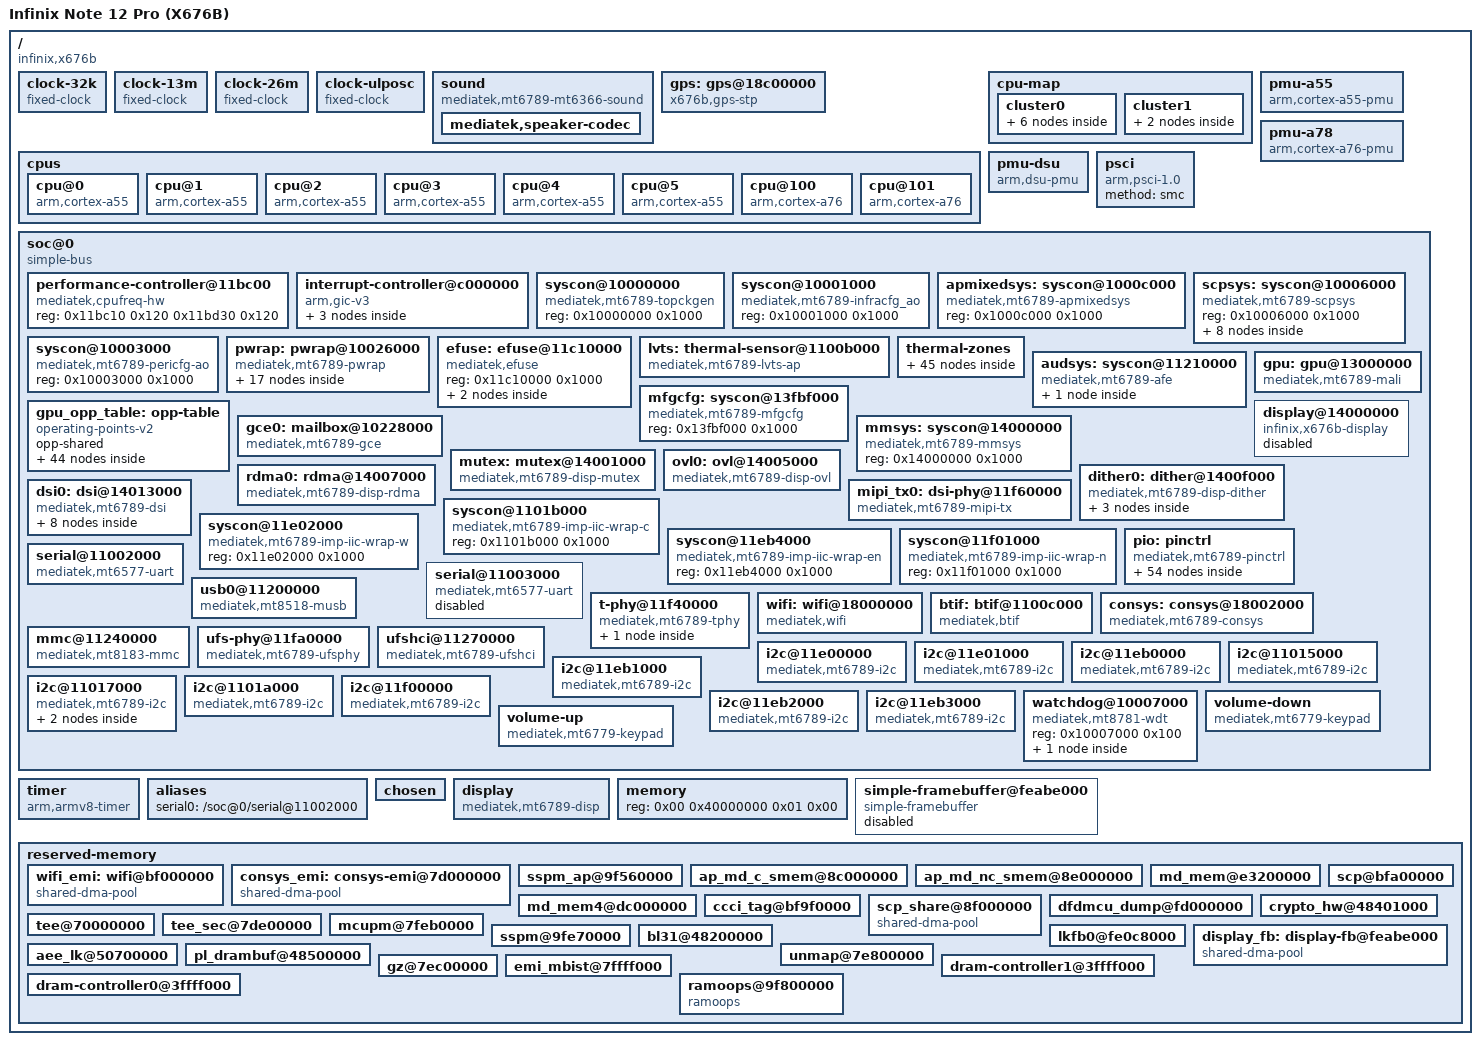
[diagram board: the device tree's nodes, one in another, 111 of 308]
/dts-v1/;

/ {
	compatible = "infinix,x676b", "mediatek,mt6789";
	#address-cells = <0x02>;
	#size-cells = <0x02>;
	interrupt-parent = <0x01>;
	model = "Infinix Note 12 Pro (X676B)";
	chassis-type = "handset";

	clock-32k {
		compatible = "fixed-clock";
		#clock-cells = <0x00>;
		clock-frequency = <0x7d00>;
		clock-output-names = "clk32k";
	};

	clock-13m {
		compatible = "fixed-clock";
		#clock-cells = <0x00>;
		clock-frequency = <0xc65d40>;
		clock-output-names = "clk13m";
	};

	clock-26m {
		compatible = "fixed-clock";
		#clock-cells = <0x00>;
		clock-frequency = <0x18cba80>;
		clock-output-names = "clk26m";
		phandle = <0x0e>;
	};

	clock-ulposc {
		compatible = "fixed-clock";
		#clock-cells = <0x00>;
		clock-frequency = <0xf7f4900>;
		clock-output-names = "ulposc";
	};

	sound: sound {
		compatible = "mediatek,mt6789-mt6366-sound";
		mediatek,platform = <&afe>;

		/* FS1559VN one-wire mode/enable line for the second
		 * (receiver / top) speaker amplifier, GPIO150.
		 */
		fs1559-extamp-gpios = <0x0d 0x96 0x00>;

		mediatek,speaker-codec {
		};
	};

	/*
	 * GPS/GNSS: STP transport + L1 LNA on GPIO25.  The vendor node is
	 * top-level (no reg); the driver only needs the pinctrl states.
	 * L5 LNA (GPIO26) is intentionally not used: that pin is the USB
	 * OTG VBUS switch on this board.
	 */
	gps: gps@18c00000 {
		compatible = "x676b,gps-stp";
		pinctrl-names = "default", "gps_l1_lna_disable",
				"gps_l1_lna_dsp_ctrl", "gps_l1_lna_enable";
		pinctrl-0 = <&gps_pins_default>;
		pinctrl-1 = <&gps_l1_lna_pins_ol>;
		pinctrl-2 = <&gps_l1_lna_pins_dsp_ctrl>;
		pinctrl-3 = <&gps_l1_lna_pins_oh>;
		emi-region = <29>;
		emi-offset = <0x400000>;
		emi-size = <0xfffff>;
		status = "okay";
	};

	cpus {
		#address-cells = <0x01>;
		#size-cells = <0x00>;

		cpu@0 {
			device_type = "cpu";
			compatible = "arm,cortex-a55";
			reg = <0x00>;
			performance-domains = <0x02 0x00>;
			enable-method = "psci";
			capacity-dmips-mhz = <0x17f>;
			phandle = <0x03>;			cpu-supply = <&mt6358_vproc12_reg>;
		};

		cpu@1 {
			device_type = "cpu";
			compatible = "arm,cortex-a55";
			reg = <0x100>;
			performance-domains = <0x02 0x00>;
			enable-method = "psci";
			capacity-dmips-mhz = <0x17f>;
			phandle = <0x04>;			cpu-supply = <&mt6358_vproc12_reg>;
		};

		cpu@2 {
			device_type = "cpu";
			compatible = "arm,cortex-a55";
			reg = <0x200>;
			performance-domains = <0x02 0x00>;
			enable-method = "psci";
			capacity-dmips-mhz = <0x17f>;
			phandle = <0x05>;			cpu-supply = <&mt6358_vproc12_reg>;
		};

		cpu@3 {
			device_type = "cpu";
			compatible = "arm,cortex-a55";
			reg = <0x300>;
			performance-domains = <0x02 0x00>;
			enable-method = "psci";
			capacity-dmips-mhz = <0x17f>;
			phandle = <0x06>;			cpu-supply = <&mt6358_vproc12_reg>;
		};

		cpu@4 {
			device_type = "cpu";
			compatible = "arm,cortex-a55";
			reg = <0x400>;
			performance-domains = <0x02 0x00>;
			enable-method = "psci";
			capacity-dmips-mhz = <0x17f>;
			phandle = <0x07>;			cpu-supply = <&mt6358_vproc12_reg>;
		};

		cpu@5 {
			device_type = "cpu";
			compatible = "arm,cortex-a55";
			reg = <0x500>;
			performance-domains = <0x02 0x00>;
			enable-method = "psci";
			capacity-dmips-mhz = <0x17f>;
			phandle = <0x08>;			cpu-supply = <&mt6358_vproc12_reg>;
		};

		cpu@100 {
			device_type = "cpu";
			compatible = "arm,cortex-a76";
			reg = <0x600>;
			performance-domains = <0x02 0x01>;
			enable-method = "psci";
			capacity-dmips-mhz = <0x400>;
			phandle = <0x09>;			cpu-supply = <&mt6358_vproc11_reg>;
		};

		cpu@101 {
			device_type = "cpu";
			compatible = "arm,cortex-a76";
			reg = <0x700>;
			performance-domains = <0x02 0x01>;
			enable-method = "psci";
			capacity-dmips-mhz = <0x400>;
			phandle = <0x0a>;			cpu-supply = <&mt6358_vproc11_reg>;
		};
	};

	cpu-map {

		cluster0 {

			core0 {
				cpu = <0x03>;
			};

			core1 {
				cpu = <0x04>;
			};

			core2 {
				cpu = <0x05>;
			};

			core3 {
				cpu = <0x06>;
			};

			core4 {
				cpu = <0x07>;
			};

			core5 {
				cpu = <0x08>;
			};
		};

		cluster1 {

			core2 {
				cpu = <0x09>;
			};

			core3 {
				cpu = <0x0a>;
			};
		};
	};

	pmu-a55 {
		compatible = "arm,cortex-a55-pmu";
		interrupt-parent = <0x01>;
		interrupts = <0x01 0x07 0x04 0x0b>;
	};

	pmu-a78 {
		compatible = "arm,cortex-a76-pmu";
		interrupt-parent = <0x01>;
		interrupts = <0x01 0x07 0x04 0x0c>;
	};

	pmu-dsu {
		compatible = "arm,dsu-pmu";
		cpus = <0x03 0x04 0x05 0x06 0x07 0x08 0x09 0x0a>;
		interrupts = <0x00 0x23 0x04 0x00>;
	};

	psci {
		compatible = "arm,psci-1.0";
		method = "smc";
	};

	soc@0 {
		compatible = "simple-bus";
		ranges = <0x00 0x00 0x00 0x20000000>;
		#address-cells = <0x01>;
		#size-cells = <0x01>;

		performance-controller@11bc00 {
			compatible = "mediatek,cpufreq-hw";
			reg = <0x11bc10 0x120 0x11bd30 0x120>;
			#performance-domain-cells = <0x01>;
			phandle = <0x02>;
		};

		interrupt-controller@c000000 {
			compatible = "arm,gic-v3";
			reg = <0xc000000 0x40000 0xc040000 0x200000>;
			#interrupt-cells = <0x04>;
			interrupt-controller;
			interrupts = <0x01 0x09 0x04 0x0b>;
			phandle = <0x01>;

			ppi-partitions {

				interrupt-partition-0 {
					affinity = <0x03 0x04 0x05 0x06 0x07 0x08>;
					phandle = <0x0b>;
				};

				interrupt-partition-1 {
					affinity = <0x09 0x0a>;
					phandle = <0x0c>;
				};
			};
		};

		syscon@10000000 {
			compatible = "mediatek,mt6789-topckgen", "mediatek,mt8781-topckgen", "syscon";
			reg = <0x10000000 0x1000>;
			#clock-cells = <0x01>;
			phandle = <0x10>;
		};

		syscon@10001000 {
			compatible = "mediatek,mt6789-infracfg_ao", "mediatek,mt8781-infracfg_ao", "syscon";
			reg = <0x10001000 0x1000>;
			#clock-cells = <0x01>;
			#reset-cells = <0x01>;
			phandle = <0x11>;

		};

		apmixedsys: syscon@1000c000 {
			compatible = "mediatek,mt6789-apmixedsys", "mediatek,mt8187-apmixedsys", "syscon";
			reg = <0x1000c000 0x1000>;
			#clock-cells = <0x01>;
		};

		scpsys: syscon@10006000 {
			compatible = "mediatek,mt6789-scpsys", "syscon", "simple-mfd";
			reg = <0x10006000 0x1000>;

			spm: power-controller {
				compatible = "mediatek,mt6789-power-controller";
				#address-cells = <0x01>;
				#size-cells = <0x00>;
				#power-domain-cells = <0x01>;

				/* CONN MTCMOS: needed by the CONSYS/Wi-Fi block */
				power-domain@1 {
					reg = <0x01>;
					#power-domain-cells = <0x00>;
				};

				/* GPU MFG hierarchy: MFG0 -> MFG1 -> MFG2/MFG3 */
				mfg0: power-domain@2 {
					reg = <0x02>;
					clocks = <0x10 105>, <0x10 104>;
					clock-names = "mfg", "alt";
					domain-supply = <&mt6358_vsram_gpu_reg>;
					#address-cells = <0x01>;
					#size-cells = <0x00>;
					#power-domain-cells = <0x01>;

					mfg1: power-domain@3 {
						reg = <0x03>;
						mediatek,infracfg = <0x11>;
						domain-supply = <&mt6358_vgpu_reg>;
						#address-cells = <0x01>;
						#size-cells = <0x00>;
						#power-domain-cells = <0x01>;

						power-domain@4 {
							reg = <0x04>;
							#power-domain-cells = <0x00>;
						};

						power-domain@5 {
							reg = <0x05>;
							#power-domain-cells = <0x00>;
						};
					};
				};

				power-domain@b {
					reg = <0x0b>;
					clocks = <0x10 118>, <0x11 37>, <0x11 32>;
					clock-names = "audio", "audio1", "audio2";
					mediatek,infracfg = <0x11>;
					#power-domain-cells = <0x00>;
				};

				/* DISP MTCMOS: needed by the display pipeline.
				 * No clocks here on purpose: the mm clock gates are
				 * handled by the mmsys driver, and we boot with
				 * clk_ignore_unused/pd_ignore_unused.
				 */
				disp: power-domain@a {
					reg = <0x0a>;
					#power-domain-cells = <0x00>;
				};
			};
		};

		syscon@10003000 {
			compatible = "mediatek,mt6789-pericfg-ao", "mediatek,mt8781-pericfg-ao", "syscon";
			reg = <0x10003000 0x1000>;
			#clock-cells = <0x01>;
		};

		/* PMIC bridge (SPI-like) + MT6366 (called mt6358 in mainline).
		 * Provides the regulators, RTC and the base for charger/battery.
		 * Clocks: infra_ao PMIC_AP(1)/PMIC_TMR(0), topckgen PWRAP_ULPOSC(0x4d).
		 * IRQ: GIC SPI 252; the PMIC IRQ arrives through the pinctrl EINT
		 * (0x0d), pin 137.
		 */
		pwrap: pwrap@10026000 {
			compatible = "mediatek,mt6789-pwrap";
			reg = <0x10026000 0x1000>;
			reg-names = "pwrap";
			interrupts = <0x00 0xfc 0x04 0x00>;
			clocks = <0x11 0x01 0x11 0x00 0x10 0x4d>;
			clock-names = "spi", "wrap", "ulposc";
			#address-cells = <0x01>;
			#size-cells = <0x00>;

			pmic: mt6358 {
				compatible = "mediatek,mt6358";
				interrupt-parent = <0x0d>;
				interrupts = <0x89 0x04 0x89 0x00>;
				interrupt-controller;
				#interrupt-cells = <0x02>;

				mt6358regulator: mt6358regulator {
					compatible = "mediatek,mt6358-regulator";

					/* SD card: VDD (VMCH) and VccQ (VMC) come from the
					 * PMIC, not from fixed regulators.
					 */
					/* supplies requested by the MT6789 consys driver */
					vcn28: vcn28 {
						regulator-name = "vcn28";
						regulator-min-microvolt = <2800000>;
						regulator-max-microvolt = <2800000>;
					};

					vcn33: vcn33 {
						regulator-name = "vcn33";
						regulator-min-microvolt = <1800000>;
						regulator-max-microvolt = <3300000>;
					};

					mt6358_vmch_reg: vmch {
						regulator-name = "vmch";
						regulator-min-microvolt = <2900000>;
						regulator-max-microvolt = <3300000>;
					};

					mt6358_vmc_reg: vmc {
						regulator-name = "vmc";
						regulator-min-microvolt = <1800000>;
						regulator-max-microvolt = <3300000>;
					};

					vcn18: vcn18 {
						regulator-name = "vcn18";
						regulator-min-microvolt = <1800000>;
						regulator-max-microvolt = <1800000>;
					};

					vpa: vpa {
						regulator-name = "vpa";
						regulator-min-microvolt = <500000>;
						regulator-max-microvolt = <3650000>;
					};

					/* GPU rails: MT6366 buck_vgpu + ldo_vsram_gpu (coupled) */
					mt6358_vgpu_reg: vgpu {
						regulator-name = "vgpu";
						regulator-min-microvolt = <0x7a120>;
						regulator-max-microvolt = <0x13bdb6>;
						regulator-ramp-delay = <0x186a>;
						regulator-enable-ramp-delay = <0xc8>;
						regulator-allowed-modes = <0x00 0x01>;
						regulator-coupled-with = <&mt6358_vsram_gpu_reg>;
						regulator-coupled-max-spread = <0x186a0>;
					};

					mt6358_vsram_gpu_reg: vsram-gpu {
						regulator-name = "vsram_gpu";
						regulator-min-microvolt = <0x7a120>;
						regulator-max-microvolt = <0x13bdb6>;
						regulator-ramp-delay = <0x186a>;
						regulator-enable-ramp-delay = <0xf0>;
						regulator-coupled-with = <&mt6358_vgpu_reg>;
						regulator-coupled-max-spread = <0x186a0>;
					};

					mt6358_vproc11_reg: vproc11 {
						regulator-name = "vproc11";
						regulator-min-microvolt = <0x7a120>;
						regulator-max-microvolt = <0x13bdb6>;
						regulator-enable-ramp-delay = <0xc8>;
						regulator-always-on;
						regulator-allowed-modes = <0x00 0x01>;
					};

					mt6358_vproc12_reg: vproc12 {
						regulator-name = "vproc12";
						regulator-min-microvolt = <0x7a120>;
						regulator-max-microvolt = <0x13bdb6>;
						regulator-enable-ramp-delay = <0xc8>;
						regulator-always-on;
						regulator-allowed-modes = <0x00 0x01>;
					};
				};

				mt6358rtc: mt6358rtc {
					compatible = "mediatek,mt6358-rtc";
					#address-cells = <0x01>;
					#size-cells = <0x01>;
				};

				mt6358keys: mt6358keys {
					compatible = "mediatek,mt6358-keys";
				};

				mt6358adc: mt6358-adc {
					compatible = "mediatek,mt6358-auxadc";
					#io-channel-cells = <0x01>;
				};

				mt6358bat: battery {
					compatible = "mediatek,mt6358-battery";
					mediatek,charger = <&rt9471_chg>;
				};

				mt6358sound: mt6358-sound {
					compatible = "mediatek,mt6358-sound";
					mediatek,dmic-mode = <0x00>;
				};
			};
		};

		/* efuse (nvmem) — used for LVTS calibration */
		efuse: efuse@11c10000 {
			compatible = "mediatek,efuse";
			reg = <0x11c10000 0x1000>;
			#address-cells = <0x01>;
			#size-cells = <0x01>;

			lvts_e_data1: data1 {
				reg = <0x1b4 0x2c>;
			};

			lvts_e_data2: data2 {
				reg = <0x2f8 0x08>;
			};
		};

		/* SoC thermal sensors. There is no mt6789 support in mainline yet, so use
		 * mt8192 (same block at 0x1100b000).
		 */
		lvts: thermal-sensor@1100b000 {
			compatible = "mediatek,mt6789-lvts-ap";
			reg = <0x1100b000 0xc00>;
			interrupts = <0x00 0xc9 0x04 0x00>;
			clocks = <0x11 0x04>;
			clock-names = "lvts_clk";
			resets = <0x11 0x00>;
			nvmem-cells = <&lvts_e_data1>, <&lvts_e_data2>;
			nvmem-cell-names = "lvts-calib-data-1", "lvts-calib-data-2";
			#thermal-sensor-cells = <0x01>;
		};

		thermal-zones {
			cpu_little1-thermal {
				polling-delay = <0x3e8>;
				polling-delay-passive = <0xfa>;
				thermal-sensors = <&lvts 0>;

				trips {
					cpu_little1_crit: trip-crit {
						temperature = <0x1adb0>;
						hysteresis = <0x7d0>;
						type = "critical";
					};
				};
			};

			cpu_little2-thermal {
				polling-delay = <0x3e8>;
				polling-delay-passive = <0xfa>;
				thermal-sensors = <&lvts 1>;

				trips {
					cpu_little2_crit: trip-crit {
						temperature = <0x1adb0>;
						hysteresis = <0x7d0>;
						type = "critical";
					};
				};
			};

			cpu_little3-thermal {
				polling-delay = <0x3e8>;
				polling-delay-passive = <0xfa>;
				thermal-sensors = <&lvts 2>;

				trips {
					cpu_little3_crit: trip-crit {
						temperature = <0x1adb0>;
						hysteresis = <0x7d0>;
						type = "critical";
					};
				};
			};

			cpu_little4-thermal {
				polling-delay = <0x3e8>;
				polling-delay-passive = <0xfa>;
				thermal-sensors = <&lvts 3>;

				trips {
					cpu_little4_crit: trip-crit {
						temperature = <0x1adb0>;
						hysteresis = <0x7d0>;
						type = "critical";
					};
				};
			};

			cpu_little5-thermal {
				polling-delay = <0x3e8>;
				polling-delay-passive = <0xfa>;
				thermal-sensors = <&lvts 4>;

				trips {
					cpu_little5_crit: trip-crit {
						temperature = <0x1adb0>;
						hysteresis = <0x7d0>;
						type = "critical";
					};
				};
			};

			cpu_little6-thermal {
				polling-delay = <0x3e8>;
				polling-delay-passive = <0xfa>;
				thermal-sensors = <&lvts 5>;

				trips {
					cpu_little6_crit: trip-crit {
						temperature = <0x1adb0>;
						hysteresis = <0x7d0>;
						type = "critical";
					};
				};
			};

			cpu_big1-thermal {
				polling-delay = <0x3e8>;
				polling-delay-passive = <0xfa>;
				thermal-sensors = <&lvts 6>;

				trips {
					cpu_big1_crit: trip-crit {
						temperature = <0x1adb0>;
						hysteresis = <0x7d0>;
						type = "critical";
					};
				};
			};

			cpu_big2-thermal {
				polling-delay = <0x3e8>;
				polling-delay-passive = <0xfa>;
				thermal-sensors = <&lvts 7>;

				trips {
					cpu_big2_crit: trip-crit {
						temperature = <0x1adb0>;
						hysteresis = <0x7d0>;
						type = "critical";
					};
				};
			};

			gpu0-thermal {
				polling-delay = <0x3e8>;
				polling-delay-passive = <0xfa>;
				thermal-sensors = <&lvts 8>;

				trips {
					gpu0_alert: trip-alert {
						temperature = <0x14c08>;
						hysteresis = <0x7d0>;
						type = "passive";
					};

					gpu0_crit: trip-crit {
						temperature = <0x1adb0>;
						hysteresis = <0x7d0>;
						type = "critical";
					};
				};

				cooling-maps {
					map0 {
						trip = <&gpu0_alert>;
						cooling-device = <&gpu 0xffffffff 0xffffffff>;
					};
				};
			};

			gpu1-thermal {
				polling-delay = <0x3e8>;
				polling-delay-passive = <0xfa>;
				thermal-sensors = <&lvts 9>;

				trips {
					gpu1_alert: trip-alert {
						temperature = <0x14c08>;
						hysteresis = <0x7d0>;
						type = "passive";
					};

					gpu1_crit: trip-crit {
						temperature = <0x1adb0>;
						hysteresis = <0x7d0>;
						type = "critical";
					};
				};

				cooling-maps {
					map0 {
						trip = <&gpu1_alert>;
						cooling-device = <&gpu 0xffffffff 0xffffffff>;
					};
				};
			};

			ts3_2-thermal {
				polling-delay = <0x3e8>;
				polling-delay-passive = <0xfa>;
				thermal-sensors = <&lvts 10>;

				trips {
					ts3_2_crit: trip-crit {
						temperature = <0x1adb0>;
						hysteresis = <0x7d0>;
						type = "critical";
					};
				};
			};

			ts3_3-thermal {
				polling-delay = <0x3e8>;
				polling-delay-passive = <0xfa>;
				thermal-sensors = <&lvts 11>;

				trips {
					ts3_3_crit: trip-crit {
						temperature = <0x1adb0>;
						hysteresis = <0x7d0>;
						type = "critical";
					};
				};
			};

			ts4_0-thermal {
				polling-delay = <0x3e8>;
				polling-delay-passive = <0xfa>;
				thermal-sensors = <&lvts 12>;

				trips {
					ts4_0_crit: trip-crit {
						temperature = <0x1adb0>;
						hysteresis = <0x7d0>;
						type = "critical";
					};
				};
			};

		};

		audsys: syscon@11210000 {
			compatible = "mediatek,mt6789-afe", "mediatek,mt8781-afe", "syscon";
			reg = <0x11210000 0x2000>;
			#clock-cells = <0x01>;
			power-domains = <&spm 0x0b>;

			afe: audio-controller {
				compatible = "mediatek,mt6789-sound";
				interrupts = <0x00 0xea 0x04 0x00>;
				topckgen = <0x10>;
				apmixedsys = <&apmixedsys>;
				infracfg = <0x11>;
				clocks = 
				<&audsys 0>,
				<&audsys 6>,
				<&audsys 7>,
				<&audsys 5>,
				<&audsys 1>,
				<&audsys 2>,
				<&audsys 4>,
				<&audsys 3>,
				<&audsys 8>,
				<&audsys 9>,
				<0x11 32>,
				<0x11 37>,
				<&audsys 14>,
				<&audsys 15>,
				<&audsys 16>,
				<&audsys 17>,
				<&audsys 18>,
				<&audsys 19>,
				<&audsys 20>,
				<&audsys 10>,
				<&audsys 11>,
				<&audsys 12>,
				<&audsys 13>,
				<&apmixedsys 11>,
				<&apmixedsys 12>,
				<0x10 117>,
				<0x10 118>,
				<0x10 3>,
				<0x10 135>,
				<0x10 36>,
				<0x10 136>,
				<0x10 94>,
				<0x10 131>,
				<0x10 38>,
				<0x10 39>,
				<0x10 132>,
				<0x10 41>,
				<0x10 42>,
				<0x10 148>,
				<0x10 149>,
				<0x10 150>,
				<0x10 151>,
				<0x10 158>,
				<0x10 159>,
				<0x10 160>,
				<0x10 161>,
				<0x10 162>,
				<0x10 163>,
				<0x10 164>,
				<0x10 142>,
				<0x10 55>;
				pinctrl-names = "aud_clk_mosi_off", "aud_clk_mosi_on",
						"aud_clk_miso_off", "aud_clk_miso_on",
						"aud_dat_mosi_off", "aud_dat_mosi_on",
						"aud_dat_miso0_off", "aud_dat_miso0_on",
						"aud_dat_miso1_off", "aud_dat_miso1_on",
						"aud_gpio_i2s0_off", "aud_gpio_i2s0_on",
						"aud_gpio_i2s3_off", "aud_gpio_i2s3_on",
						"vow_dat_miso_off", "vow_dat_miso_on",
						"vow_clk_miso_off", "vow_clk_miso_on";
				pinctrl-0 = <&aud_clk_mosi_off>;
				pinctrl-1 = <&aud_clk_mosi_on>;
				pinctrl-2 = <&aud_clk_miso_off>;
				pinctrl-3 = <&aud_clk_miso_on>;
				pinctrl-4 = <&aud_dat_mosi_off>;
				pinctrl-5 = <&aud_dat_mosi_on>;
				pinctrl-6 = <&aud_dat_miso0_off>;
				pinctrl-7 = <&aud_dat_miso0_on>;
				pinctrl-8 = <&aud_dat_miso1_off>;
				pinctrl-9 = <&aud_dat_miso1_on>;
				pinctrl-10 = <&aud_gpio_i2s0_off>;
				pinctrl-11 = <&aud_gpio_i2s0_on>;
				pinctrl-12 = <&aud_gpio_i2s3_off>;
				pinctrl-13 = <&aud_gpio_i2s3_on>;
				pinctrl-14 = <&vow_dat_miso_off>;
				pinctrl-15 = <&vow_dat_miso_on>;
				pinctrl-16 = <&vow_clk_miso_off>;
				pinctrl-17 = <&vow_clk_miso_on>;
				clock-names = 
				      "aud_afe_clk",
				      "aud_dac_clk",
				      "aud_dac_predis_clk",
				      "aud_adc_clk",
				      "aud_apll22m_clk",
				      "aud_apll24m_clk",
				      "aud_apll1_tuner_clk",
				      "aud_apll2_tuner_clk",
				      "aud_tml_clk",
				      "aud_nle",
				      "aud_infra_clk",
				      "aud_infra_26m_clk",
				      "aud_general3_asrc",
				      "aud_connsys_i2s_asrc",
				      "aud_general1_asrc",
				      "aud_general2_asrc",
				      "aud_dac_hires_clk",
				      "aud_adc_hires_clk",
				      "aud_adc_hires_tml",
				      "aud_i2s1_bclk",
				      "aud_i2s2_bclk",
				      "aud_i2s3_bclk",
				      "aud_i2s4_bclk",
				      "aud_clk_apmixed_apll1",
				      "aud_clk_apmixed_apll2",
				      "top_mux_audio",
				      "top_mux_audio_int",
				      "top_mainpll_d4_d4",
				      "top_mux_aud_1",
				      "top_apll1_ck",
				      "top_mux_aud_2",
				      "top_apll2_ck",
				      "top_mux_aud_eng1",
				      "top_apll1_d4",
				      "top_apll1_d8",
				      "top_mux_aud_eng2",
				      "top_apll2_d4",
				      "top_apll2_d8",
				      "top_i2s0_m_sel",
				      "top_i2s1_m_sel",
				      "top_i2s2_m_sel",
				      "top_i2s3_m_sel",
				      "top_apll12_div0",
				      "top_apll12_div1",
				      "top_apll12_div2",
				      "top_apll12_div3",
				      "top_apll12_div4",
				      "top_apll12_divb",
				      "top_apll12_div5",
				      "top_mux_audio_h",
				      "top_clk26m_clk";
			};
		};

		mfgcfg: syscon@13fbf000 {
			compatible = "mediatek,mt6789-mfgcfg", "mediatek,mt6789-mfg", "mediatek,mt8781-mfg", "syscon";
			reg = <0x13fbf000 0x1000>;
			#clock-cells = <0x01>;
		};

		gpu: gpu@13000000 {
			compatible = "mediatek,mt6789-mali", "arm,mali-valhall-jm";
			reg = <0x13000000 0x4000>;
			interrupts = <0x00 0x18e 0x04 0x00>,
				     <0x00 0x18d 0x04 0x00>,
				     <0x00 0x18c 0x04 0x00>;
			interrupt-names = "job", "mmu", "gpu";
			clocks = <&mfgcfg 0x00>;
			power-domains = <&spm 0x04>, <&spm 0x05>;
			power-domain-names = "core0", "core1";
			operating-points-v2 = <&gpu_opp_table>;
			mali-supply = <&mt6358_vgpu_reg>;
			#cooling-cells = <0x02>;
			status = "okay";
		};

		gpu_opp_table: opp-table {
			compatible = "operating-points-v2";
			opp-shared;

			opp00 { opp-hz = /bits/ 64 <1100000000>; opp-microvolt = <850000>; };
			opp01 { opp-hz = /bits/ 64 <1086000000>; opp-microvolt = <843750>; };
			opp02 { opp-hz = /bits/ 64 <1072000000>; opp-microvolt = <837500>; };
			opp03 { opp-hz = /bits/ 64 <1058000000>; opp-microvolt = <831250>; };
			opp04 { opp-hz = /bits/ 64 <1045000000>; opp-microvolt = <825000>; };
			opp05 { opp-hz = /bits/ 64 <1031000000>; opp-microvolt = <818750>; };
			opp06 { opp-hz = /bits/ 64 <1017000000>; opp-microvolt = <812500>; };
			opp07 { opp-hz = /bits/ 64 <1003000000>; opp-microvolt = <806250>; };
			opp09 { opp-hz = /bits/ 64 <976000000>; opp-microvolt = <793750>; };
			opp10 { opp-hz = /bits/ 64 <962000000>; opp-microvolt = <781250>; };
			opp11 { opp-hz = /bits/ 64 <948000000>; opp-microvolt = <775000>; };
			opp12 { opp-hz = /bits/ 64 <935000000>; opp-microvolt = <768750>; };
			opp13 { opp-hz = /bits/ 64 <921000000>; opp-microvolt = <762500>; };
			opp14 { opp-hz = /bits/ 64 <907000000>; opp-microvolt = <756250>; };
			opp15 { opp-hz = /bits/ 64 <893000000>; opp-microvolt = <750000>; };
			opp16 { opp-hz = /bits/ 64 <880000000>; opp-microvolt = <743750>; };
			opp17 { opp-hz = /bits/ 64 <868000000>; opp-microvolt = <737500>; };
			opp18 { opp-hz = /bits/ 64 <857000000>; opp-microvolt = <731250>; };
			opp19 { opp-hz = /bits/ 64 <846000000>; opp-microvolt = <725000>; };
			opp20 { opp-hz = /bits/ 64 <835000000>; opp-microvolt = <718750>; };
			opp21 { opp-hz = /bits/ 64 <823000000>; opp-microvolt = <712500>; };
			opp22 { opp-hz = /bits/ 64 <812000000>; opp-microvolt = <706250>; };
			opp23 { opp-hz = /bits/ 64 <801000000>; opp-microvolt = <706250>; };
			opp24 { opp-hz = /bits/ 64 <790000000>; opp-microvolt = <700000>; };
			opp25 { opp-hz = /bits/ 64 <778000000>; opp-microvolt = <693750>; };
			opp26 { opp-hz = /bits/ 64 <767000000>; opp-microvolt = <687500>; };
			opp27 { opp-hz = /bits/ 64 <756000000>; opp-microvolt = <681250>; };
			opp28 { opp-hz = /bits/ 64 <745000000>; opp-microvolt = <675000>; };
			opp29 { opp-hz = /bits/ 64 <733000000>; opp-microvolt = <668750>; };
			opp30 { opp-hz = /bits/ 64 <722000000>; opp-microvolt = <662500>; };
			opp31 { opp-hz = /bits/ 64 <711000000>; opp-microvolt = <656250>; };
			opp32 { opp-hz = /bits/ 64 <700000000>; opp-microvolt = <650000>; };
			opp33 { opp-hz = /bits/ 64 <674000000>; opp-microvolt = <643750>; };
			opp34 { opp-hz = /bits/ 64 <648000000>; opp-microvolt = <637500>; };
			opp35 { opp-hz = /bits/ 64 <622000000>; opp-microvolt = <631250>; };
			opp36 { opp-hz = /bits/ 64 <596000000>; opp-microvolt = <625000>; };
			opp37 { opp-hz = /bits/ 64 <570000000>; opp-microvolt = <618750>; };
			opp38 { opp-hz = /bits/ 64 <545000000>; opp-microvolt = <612500>; };
			opp39 { opp-hz = /bits/ 64 <519000000>; opp-microvolt = <606250>; };
			opp40 { opp-hz = /bits/ 64 <493000000>; opp-microvolt = <600000>; };
			opp41 { opp-hz = /bits/ 64 <467000000>; opp-microvolt = <593750>; };
			opp42 { opp-hz = /bits/ 64 <441000000>; opp-microvolt = <587500>; };
			opp43 { opp-hz = /bits/ 64 <415000000>; opp-microvolt = <581250>; };
			opp44 { opp-hz = /bits/ 64 <390000000>; opp-microvolt = <575000>; };
		};

		gce0: mailbox@10228000 {
			compatible = "mediatek,mt6789-gce";
			reg = <0x10228000 0x4000>;
			interrupts = <0x00 235 0x04 0x00>;
			#mbox-cells = <0x02>;
			clocks = <0x11 0x02>;		/* infracfg_ao CLK_IFRAO_GCE */
			clock-names = "gce";
		};

		mmsys: syscon@14000000 {
			compatible = "mediatek,mt6789-mmsys", "mediatek,mt8781-mmsys", "syscon";
			reg = <0x14000000 0x1000>;
			#clock-cells = <0x01>;
		};

		/* Minimal DRM/KMS driver reusing the LK-initialized pipeline */
		display@14000000 {
			compatible = "infinix,x676b-display";
			reg = <0x14000000 0x14000>;
			/* Scanout buffer lives where LK had its framebuffer, so the
			 * display SMI window set up by LK covers it.
			 */
			memory-region = <&display_fb>;
			status = "disabled";
		};

		/* ---- mainline mediatek-drm pipeline (X676B) ---- */
		mutex: mutex@14001000 {
			compatible = "mediatek,mt6789-disp-mutex";
			reg = <0x14001000 0x1000>;
			interrupts = <0x00 285 0x04 0x00>;
			power-domains = <&spm 0x0a>;
			clocks = <&mmsys 0x00>;		/* CLK_MM_DISP_MUTEX0 */
			status = "okay";
		};

		ovl0: ovl@14005000 {
			compatible = "mediatek,mt6789-disp-ovl";
			reg = <0x14005000 0x1000>;
			interrupts = <0x00 287 0x04 0x00>;
			power-domains = <&spm 0x0a>;
			clocks = <&mmsys 0x02>;		/* CLK_MM_DISP_OVL0 */
			status = "okay";
		};

		rdma0: rdma@14007000 {
			compatible = "mediatek,mt6789-disp-rdma";
			reg = <0x14007000 0x1000>;
			interrupts = <0x00 289 0x04 0x00>;
			power-domains = <&spm 0x0a>;
			clocks = <&mmsys 0x03>;		/* CLK_MM_DISP_RDMA0 */
			mediatek,rdma-fifo-size = <48992>;
			status = "okay";
		};

		dither0: dither@1400f000 {
			compatible = "mediatek,mt6789-disp-dither";
			reg = <0x1400f000 0x1000>;
			interrupts = <0x00 297 0x04 0x00>;
			power-domains = <&spm 0x0a>;
			clocks = <&mmsys 0x0e>;		/* CLK_MM_DISP_DITHER0 */
			status = "okay";

			ports {
				#address-cells = <0x01>;
				#size-cells = <0x00>;

				port@0 {
					reg = <0x00>;
					dither0_out: endpoint {
						remote-endpoint = <&dsi0_in>;
					};
				};
			};
		};

		mipi_tx0: dsi-phy@11f60000 {
			compatible = "mediatek,mt6789-mipi-tx",
			             "mediatek,mt8183-mipi-tx";
			reg = <0x11f60000 0x1000>;
			clocks = <0x0e>;		/* clk26m */
			#clock-cells = <0x00>;
			#phy-cells = <0x00>;
			clock-output-names = "mipi_tx0_pll";
			status = "okay";
		};

		dsi0: dsi@14013000 {
			compatible = "mediatek,mt6789-dsi";
			reg = <0x14013000 0x1000>;
			interrupts = <0x00 301 0x04 0x00>;
			power-domains = <&spm 0x0a>;
			clocks = <&mmsys 0x10>,		/* CLK_MM_DSI0 */
			         <&mmsys 0x15>,		/* CLK_MM_DSI0_DSI_CK_DOMAIN */
			         <&mipi_tx0>;
			clock-names = "engine", "digital", "hs";
			phys = <&mipi_tx0>;
			phy-names = "dphy";
			/*
			 * The vendor runs this panel at 1120 Mbit/s per lane
			 * (4 lanes).  It does not follow from the 167.67 MHz
			 * mode clock: in command mode the RDMA feeds the DSI
			 * as fast as the link allows, and 15.5 ms per frame
			 * (the derived 1006 Mbit/s) leaves no room for 60 Hz.
			 */
			mediatek,data-rate-mbps = <1120>;
			#address-cells = <0x01>;
			#size-cells = <0x00>;
			status = "okay";

			panel1: panel@0 {
				compatible = "ilitek,ili7835";
				reg = <0x00>;
				reset-gpios = <&pio 0x55 0x00>;	/* pin 85 */
				bias-gpios = <&pio 0x40 0x00>;	/* pin 64 */

				port {
					#address-cells = <0x01>;
					#size-cells = <0x00>;

					panel_in: endpoint@0 {
						reg = <0x00>;
						remote-endpoint = <&dsi0_out>;
					};
				};
			};

			ports {
				#address-cells = <0x01>;
				#size-cells = <0x00>;

				port@0 {
					#address-cells = <0x01>;
					#size-cells = <0x00>;
					reg = <0x00>;
					dsi0_in: endpoint@0 {
						reg = <0x00>;
						remote-endpoint = <&dither0_out>;
					};
				};

				port@1 {
					#address-cells = <0x01>;
					#size-cells = <0x00>;
					reg = <0x01>;
					dsi0_out: endpoint@0 {
						reg = <0x00>;
						remote-endpoint = <&panel_in>;
					};
				};
			};
		};

		syscon@1101b000 {
			compatible = "mediatek,mt6789-imp-iic-wrap-c", "syscon";
			phandle = <0x30>;
			reg = <0x1101b000 0x1000>;
			#clock-cells = <0x01>;
		};

		syscon@11e02000 {
			compatible = "mediatek,mt6789-imp-iic-wrap-w", "syscon";
			phandle = <0x31>;
			reg = <0x11e02000 0x1000>;
			#clock-cells = <0x01>;
		};

		syscon@11eb4000 {
			compatible = "mediatek,mt6789-imp-iic-wrap-en", "syscon";
			phandle = <0x32>;
			reg = <0x11eb4000 0x1000>;
			#clock-cells = <0x01>;
		};

		syscon@11f01000 {
			compatible = "mediatek,mt6789-imp-iic-wrap-n", "syscon";
			phandle = <0x33>;
			reg = <0x11f01000 0x1000>;
			#clock-cells = <0x01>;
		};

		pio: pinctrl {
			compatible = "mediatek,mt6789-pinctrl", "mediatek,mt8781-pinctrl";
			reg = <0x10005000 0x1000 0x11c30000 0x1000 0x11d10000 0x1000 0x11d40000 0x1000 0x11e20000 0x1000 0x11e60000 0x1000 0x11ea0000 0x1000 0x1000b000 0x1000>;
			reg-names = "iocfg0", "iocfg_rb", "iocfg_bm", "iocfg_br", "iocfg_lm", "iocfg_bl", "iocfg_rt", "eint";
			gpio-controller;
			#gpio-cells = <0x02>;
			gpio-ranges = <&pio 0x00 0x00 0xbc>;

			interrupt-controller;
			#interrupt-cells = <0x02>;
			/* EINT summary IRQ: GIC SPI 244 (stock eint node
			 * apirq@1000b000 uses <0 0xf4 4 0>); registers and
			 * reg-names already include the "eint" region.
			 */
			interrupts = <0x00 0xf4 0x04 0x00>;
			phandle = <0x0d>;

			/* GPIO12 powers the gate IC that feeds the speaker
			 * amplifier (stock DT: gate-power-gpios = <&pio 12 0>).
			 * Without it the speaker amp stays unpowered.
			 */
			gate_ic_power: gate-ic-power {
				gpio-hog;
				gpios = <0x0c 0x00>;
				output-high;
				line-name = "gate-ic-power";
			};

			/* GPIO153 enables the speaker amplifier (stock overlay:
			 * fs1559_dual_speaker_gpio = <&pio 153 0>). It is
			 * required in addition to the gate IC power above.
			 */
			spk_amp_enable: spk-amp-enable {
				gpio-hog;
				gpios = <0x99 0x00>;
				output-high;
				line-name = "spk-amp-enable";
			};
					mmc1-pins {
				phandle = <0x14>;

				pins-cmd-dat {
					pinmux = <0x4901 0x4a01 0x4b01 0x4c01 0x4801>;
					input-enable;
					/* MT6789 drive steps are 2/4 mA: 3 mA is
					 * rejected and would abort the whole group,
					 * leaving the lines without pull-ups.
					 */
					drive-strength = <0x04>;
					bias-pull-up = <0x65>;
					};

				pins-clk {
					pinmux = <0x4701>;
					drive-strength = <0x04>;
					bias-pull-down = <0x66>;
					};
			};



			aud_clk_mosi_off: aud_clk_mosi_off {

				pins_cmd0_dat {
					pinmux = <0xa900>;
					input-enable;
					bias-pull-down;
				};
			};

			aud_clk_mosi_on: aud_clk_mosi_on {

				pins_cmd0_dat {
					pinmux = <0xa901>;
					input-schmitt-enable;
					bias-disable;
				};
			};

			aud_clk_miso_off: aud_clk_miso_off {

				pins_cmd0_dat {
					pinmux = <0xad00>;
					input-enable;
					bias-pull-down;
				};
			};

			aud_clk_miso_on: aud_clk_miso_on {

				pins_cmd0_dat {
					pinmux = <0xad01>;
					input-schmitt-enable;
					bias-disable;
				};
			};

			aud_dat_mosi_off: aud_dat_mosi_off {

				pins_cmd0_dat {
					pinmux = <0xab00>;
					input-enable;
					bias-pull-down;
				};

				pins_cmd1_dat {
					pinmux = <0xac00>;
					input-enable;
					bias-pull-down;
				};
			};

			aud_dat_mosi_on: aud_dat_mosi_on {

				pins_cmd0_dat {
					pinmux = <0xab01>;
					input-schmitt-enable;
					bias-disable;
				};

				pins_cmd1_dat {
					pinmux = <0xac01>;
					input-schmitt-enable;
					bias-disable;
				};
			};

			aud_dat_miso0_off: aud_dat_miso0_off {

				pins_cmd1_dat {
					pinmux = <0xaf00>;
					input-enable;
					bias-pull-down;
				};
			};

			aud_dat_miso0_on: aud_dat_miso0_on {

				pins_cmd1_dat {
					pinmux = <0xaf01>;
					input-schmitt-enable;
					bias-disable;
				};
			};

			aud_dat_miso1_off: aud_dat_miso1_off {

				pins_cmd1_dat {
					pinmux = <0xb000>;
					input-enable;
					bias-disable;
				};
			};

			aud_dat_miso1_on: aud_dat_miso1_on {

				pins_cmd1_dat {
					pinmux = <0xb001>;
					input-schmitt-enable;
					bias-disable;
				};
			};

			aud_gpio_i2s0_off: aud_gpio_i2s0_off {

				pins_cmd1_dat {
					pinmux = <0x3500>;
					input-enable;
					bias-pull-down;
				};
			};

			aud_gpio_i2s0_on: aud_gpio_i2s0_on {

				pins_cmd1_dat {
					pinmux = <0x3502>;
					input-schmitt-enable;
					bias-disable;
				};
			};

			gps_pins_default: gps_default {
			};

			gps_l1_lna_pins_ol: gps_l1_lna@0 {
				pins_cmd_dat {
					output-low;
					pinmux = <0x1900>;
				};
			};

			gps_l1_lna_pins_dsp_ctrl: gps_l1_lna@1 {
				pins_cmd_dat {
					pinmux = <0x1902>;
				};
			};

			gps_l1_lna_pins_oh: gps_l1_lna@2 {
				pins_cmd_dat {
					output-high;
					pinmux = <0x1900>;
				};
			};

			aud_gpio_i2s3_off: aud_gpio_i2s3_off {

				pins_cmd1_dat {
					pinmux = <0x3200>;
					input-enable;
					bias-pull-down;
				};

				pins_cmd2_dat {
					pinmux = <0x3300>;
					input-enable;
					bias-pull-down;
				};

				pins_cmd3_dat {
					pinmux = <0x3400>;
					input-enable;
					bias-pull-down;
				};
			};

			aud_gpio_i2s3_on: aud_gpio_i2s3_on {

				pins_cmd1_dat {
					pinmux = <0x3202>;
					input-schmitt-enable;
					bias-disable;
				};

				pins_cmd2_dat {
					pinmux = <0x3302>;
					input-schmitt-enable;
					bias-disable;
				};

				pins_cmd3_dat {
					pinmux = <0x3402>;
					input-schmitt-enable;
					bias-disable;
				};
			};

			vow_dat_miso_off: vow_dat_miso_off {

				pins_cmd1_dat {
					pinmux = <0xaf00>;
					input-enable;
					bias-pull-down;
				};
			};

			vow_dat_miso_on: vow_dat_miso_on {

				pins_cmd1_dat {
					pinmux = <0xaf04>;
					input-schmitt-enable;
					bias-disable;
				};
			};

			vow_clk_miso_off: vow_clk_miso_off {

				pins_cmd1_dat {
					pinmux = <0xb000>;
					input-enable;
					bias-pull-down;
				};
			};

			vow_clk_miso_on: vow_clk_miso_on {

				pins_cmd1_dat {
					pinmux = <0xb004>;
					input-schmitt-enable;
					bias-disable;
				};
			};
};

		serial@11002000 {
			compatible = "mediatek,mt6577-uart";
			reg = <0x11002000 0x1000>;
			interrupts = <0x00 0x8d 0x04 0x00>;
			clocks = <0x0e 0x0e>;
			clock-names = "baud", "bus";
			status = "okay";
		};

		serial@11003000 {
			compatible = "mediatek,mt6577-uart";
			reg = <0x11003000 0x1000>;
			interrupts = <0x00 0x18e 0x04 0x00>;
			clock-names = "baud", "bus";
			status = "disabled";
		};

		usb0@11200000 {
			compatible = "mediatek,mt8518-musb", "mediatek,mtk-musb";
			reg = <0x11200000 0x10000>;
			interrupts = <0x00 0x80 0x04 0x00>;
			interrupt-names = "mc";
			phys = <0x0f 0x03>;
			clocks = <0x0e 0x0e 0x0e>;
			clock-names = "main", "mcu", "univpll";
			#address-cells = <0x02>;
			#size-cells = <0x02>;
			ranges;
			status = "okay";
			/*
			 * OTG: the role is switched at runtime through
			 * /sys/class/usb_role/11200000.usb0-role-switch/role.
			 * A userland helper watches the ID GPIO (69) and enables
			 * the RT9471 OTG boost + GPIO26 only in host mode.
			 */
			dr_mode = "otg";
			maximum-speed = "high-speed";
		};

		t-phy@11f40000 {
			compatible = "mediatek,mt6789-tphy", "mediatek,generic-tphy-v2";
			#address-cells = <0x02>;
			#size-cells = <0x02>;
			/*
			 * Identity mapping: the U2 PHY child's reg is absolute
			 * (0x11f40000, size 0x700).  With the old relative
			 * "<0 0x700>" the driver programmed 0x11f407xx, so
			 * PHY_MODE_USB_HOST never reached the real IDDIG bits.
			 */
			ranges;
			status = "okay";

			usb-phy@11f40000 {
				reg = <0x00 0x11f40000 0x00 0x700>;
				clocks = <0x0e>;
				clock-names = "ref";
				#phy-cells = <0x01>;
				status = "okay";
				mediatek,eye-vrt = <0x04>;
				mediatek,eye-term = <0x04>;
				mediatek,rev4 = <0x01>;
				mediatek,rx_sqth = <0x05>;
				mediatek,discth = <0x07>;
				phandle = <0x0f>;
			};
		};

		/* Wi-Fi/BT/FM/GPS connectivity (CONNAC2 + MT6631 A-die).
		 * Registers, interrupts and EMI properties are taken from the
		 * stock DT; supplies and the PD are wired to mainline nodes.
		 */
		/* Wi-Fi MAC/WFDMA (CONNAC2). Used by the gen4m WLAN driver,
		 * which downloads its own firmware and does not need WMT.
		 */
		wifi: wifi@18000000 {
			compatible = "mediatek,wifi";
			reg = <0x18000000 0x100000>;
			interrupts = <0x00 0x199 0x04 0x00>;
			memory-region = <&wifi_emi>;
			emi-addr = <0x7d000000>;
			emi-size = <0x600000>;
			emi-alignment = <0x1000000>;
			emi-max-addr = <0xc0000000>;
		};

		btif: btif@1100c000 {
			compatible = "mediatek,btif";
			reg = <0x1100c000 0x1000>,
			      <0x10217b00 0x80>,
			      <0x10217b80 0x80>;
			interrupts = <0x00 0xbe 0x04 0x00>,
				     <0x00 0xb8 0x04 0x00>,
				     <0x00 0xb9 0x04 0x00>;
			clocks = <0x11 18>, <0x11 61>;
			clock-names = "btifc", "apdmac";
		};

		consys: consys@18002000 {
			compatible = "mediatek,mt6789-consys";
			#thermal-sensor-cells = <0x00>;
			reg = <0x18002000 0x1000>,
			      <0x10007000 0x100>,
			      <0x10001000 0x1000>,
			      <0x10006000 0x1000>,
			      <0x18007000 0x1000>,
			      <0x180b1000 0x1000>,
			      <0x180a3000 0x1000>,
			      <0x180a5000 0x800>,
			      <0x180c1000 0x1000>,
			      <0x18004000 0x1000>,
			      <0x1024c000 0x40>,
			      <0x10003000 0x1000>;
			interrupts = <0x00 0x19a 0x04 0x00>,
				     <0x00 0x6f 0x04 0x00>,
				     <0x00 0x19b 0x04 0x00>;
			clocks = <0x11 0x38>;
			clock-names = "ccif";
			power-domains = <&spm 0x01>;
			pmic = <&pmic>;
			emi-addr = <0x00>;
			emi-size = <0x600000>;
			emi-alignment = <0x1000000>;
			emi-max-addr = <0x80000000>;
			memory-region = <&consys_emi>;
			vcn18-supply = <&vcn18>;
			vcn28-supply = <&vcn28>;
			vcn33_bt-supply = <&vcn33>;
			vcn33_wifi-supply = <&vcn33>;
			status = "okay";
		};

		mmc@11240000 {
			compatible = "mediatek,mt8183-mmc";
			reg = <0x11240000 0x1000 0x11ef0000 0x1000>;
			clocks = <0x10 0x74 0x11 0x15 0x11 0x1c>;
			clock-names = "source", "hclk", "source_cg";
			interrupts = <0x00 0x87 0x04 0x00>;
			bus-width = <0x04>;
			max-frequency = <0xbebc200>;
			ocr-voltage = <0x30000>;
			cap-sd-highspeed;
			vmmc-supply = <&mt6358_vmch_reg>;
			vqmmc-supply = <&mt6358_vmc_reg>;
			pinctrl-names = "default", "state_uhs";
			pinctrl-0 = <0x14>;
			pinctrl-1 = <0x14>;
			no-mmc;
			no-sdio;
			builtin-cd = <0x00>;
			status = "okay";
			r_smpl = <0x00>;
			/* CD is active-high (stock DT: <&pio 7 0>); with
			 * ACTIVE_LOW the driver probes a slot with no card.
			 */
			cd-gpios = <0x0d 0x07 0x00>;
		};


				ufs-phy@11fa0000 {
			compatible = "mediatek,mt6789-ufsphy", "mediatek,mt8183-ufsphy";
			reg = <0x11fa0000 0xc000>;
			clocks = <0x11 0x29 0x11 0x2b>;
			clock-names = "unipro", "mp";
			#phy-cells = <0x00>;
			phandle = <0x34>;
			status = "okay";
		};

ufshci@11270000 {
			compatible = "mediatek,mt6789-ufshci", "mediatek,mt8183-ufshci";
			reg = <0x11270000 0x2300>;
			interrupts = <0x00 0x89 0x04 0x00>;
			phys = <0x34>;
			clocks = <0x11 0x2f 0x10 0x86>;
			clock-names = "ufs", "ufs_sel";
			freq-table-hz = <0x00 0x00>, <0x00 0x00>;
			resets = <0x11 0x01 0x11 0x02 0x11 0x03>;
			reset-names = "hci_rst", "unipro_rst", "crypto_rst";
			mediatek,ufs-disable-mcq;
			mediatek,ufs-broken-vcc;
			status = "okay";
		
		};

		i2c@11e00000 {
			compatible = "mediatek,mt6789-i2c", "mediatek,mt8781-i2c";
			reg = <0x11e00000 0x1000 0x10217080 0x80>;
			interrupts = <0x00 0x90 0x04 0x00>;
			clock-names = "main", "dma";
			clocks = <0x31 0x0>, <0x11 61>;
			clock-div = <0x01>;
		};

		i2c@11e01000 {
			compatible = "mediatek,mt6789-i2c", "mediatek,mt8781-i2c";
			reg = <0x11e01000 0x1000 0x10217100 0x80>;
			interrupts = <0x00 0x91 0x04 0x00>;
			clock-names = "main", "dma";
			clocks = <0x31 0x1>, <0x11 61>;
			clock-div = <0x01>;
		};

		i2c@11eb0000 {
			compatible = "mediatek,mt6789-i2c", "mediatek,mt8781-i2c";
			reg = <0x11eb0000 0x1000 0x10217180 0x80>;
			interrupts = <0x00 0x92 0x04 0x00>;
			clock-names = "main", "dma";
			clocks = <0x32 0x0>, <0x11 61>;
			clock-div = <0x01>;
		};

		i2c@11015000 {
			compatible = "mediatek,mt6789-i2c", "mediatek,mt8781-i2c";
			reg = <0x11015000 0x1000 0x10217280 0x80>;
			interrupts = <0x00 0x93 0x04 0x00>;
			clock-names = "main", "dma";
			clocks = <0x30 0x0>, <0x11 61>;
			clock-div = <0x01>;
		};

		i2c@11eb1000 {
			compatible = "mediatek,mt6789-i2c", "mediatek,mt8781-i2c";
			reg = <0x11eb1000 0x1000 0x10217300 0x80>;
			interrupts = <0x00 0x94 0x04 0x00>;
			clock-names = "main", "dma";
			clocks = <0x32 0x1>, <0x11 61>;
			clock-div = <0x01>;
		};

		i2c@11017000 {
			compatible = "mediatek,mt6789-i2c", "mediatek,mt8781-i2c";
			reg = <0x11017000 0x1000 0x10217400 0x80>;
			interrupts = <0x00 0x95 0x04 0x00>;
			clock-names = "main", "dma";
			clocks = <0x30 0x1>, <0x11 61>;
			clock-div = <0x01>;
			#address-cells = <0x01>;
			#size-cells = <0x00>;

			rt9471_chg: charger@53 {
				compatible = "richtek,rt9471";
				reg = <0x53>;
				wakeup-source;
				interrupts-extended = <0x0d 0x04 0x02>;
				status = "okay";

				usb-otg-vbus-regulator {
					regulator-name = "usb-otg-vbus";
					regulator-min-microvolt = <0x4a0150>;
					regulator-max-microvolt = <0x50df20>;
					regulator-min-microamp = <0x7a120>;
					regulator-max-microamp = <0x124f80>;
				};
			};
		};

		i2c@1101a000 {
			compatible = "mediatek,mt6789-i2c", "mediatek,mt8781-i2c";
			reg = <0x1101a000 0x1000 0x10217480 0x80>;
			interrupts = <0x00 0x96 0x04 0x00>;
			clock-names = "main", "dma";
			clocks = <0x30 0x2>, <0x11 61>;
			clock-div = <0x01>;
		};

		i2c@11f00000 {
			compatible = "mediatek,mt6789-i2c", "mediatek,mt8781-i2c";
			reg = <0x11f00000 0x1000 0x10217500 0x80>;
			interrupts = <0x00 0x97 0x04 0x00>;
			clock-names = "main", "dma";
			clocks = <0x33 0x0>, <0x11 61>;
			clock-div = <0x01>;
		};

		i2c@11eb2000 {
			compatible = "mediatek,mt6789-i2c", "mediatek,mt8781-i2c";
			reg = <0x11eb2000 0x1000 0x10217600 0x80>;
			interrupts = <0x00 0x98 0x04 0x00>;
			clock-names = "main", "dma";
			clocks = <0x32 0x2>, <0x11 61>;
			clock-div = <0x01>;
		};

		i2c@11eb3000 {
			compatible = "mediatek,mt6789-i2c", "mediatek,mt8781-i2c";
			reg = <0x11eb3000 0x1000 0x10217700 0x80>;
			interrupts = <0x00 0x99 0x04 0x00>;
			clock-names = "main", "dma";
			clocks = <0x32 0x3>, <0x11 61>;
			clock-div = <0x01>;
		};

		watchdog@10007000 {
			compatible = "mediatek,mt8781-wdt", "mediatek,mt6589-wdt", "syscon";
			reg = <0x10007000 0x100>;

			reboot-mode {
				compatible = "syscon-reboot-mode";
				offset = <0x24>;
				mask = <0x0f>;
				mode-charger = <0x01>;
				mode-recovery = <0x02>;
				mode-bootloader = <0x03>;
				mode-dm-verity-dev-corrupt = <0x04>;
				mode-kpoc = <0x05>;
				mode-ddr-reserve = <0x06>;
				mode-meta = <0x07>;
				mode-rpmbpk = <0x08>;
			};
		};

		volume-down {
			compatible = "mediatek,mt6779-keypad";
			reg = <0x10010000 0x1000>;
			label = "vdown";
			1,code = <0x72>;
			mediatek,matrix-val = <0xbfdf>;
			mediatek,matrix-reg = <0x0c>;
			status = "okay";
		};

		volume-up {
			compatible = "mediatek,mt6779-keypad";
			reg = <0x10010000 0x1000>;
			label = "vup";
			1,code = <0x73>;
			mediatek,matrix-val = <0xdfef>;
			mediatek,matrix-reg = <0x0c>;
			status = "okay";
		};
	};

	timer {
		compatible = "arm,armv8-timer";
		interrupt-parent = <0x01>;
		interrupts = <0x01 0x0d 0x08 0x00 0x01 0x0e 0x08 0x00 0x01 0x0b 0x08 0x00 0x01 0x0a 0x08 0x00>;
	};

	aliases {
		serial0 = "/soc@0/serial@11002000";
	};

	chosen {
		#address-cells = <0x02>;
		#size-cells = <0x02>;
		ranges;
	};

	display {
		compatible = "mediatek,mt6789-disp";
		bootph-all;
	};

	memory {
		device_type = "memory";
		reg = <0x00 0x40000000 0x01 0x00>;
	};

	simple-framebuffer@feabe000 {
		compatible = "simple-framebuffer";
		status = "disabled";
		reg = <0x00 0xfeabe000 0x00 0x9e6000>;
		width = <0x438>;
		height = <0x960>;
		stride = <0x10e0>;
		format = "a8r8g8b8";
		/* physical panel size ~6.7" (1080x2400, 20:9) */
		width-mm = <0x46>;
		height-mm = <0x9b>;
	};

	reserved-memory {
		#address-cells = <0x02>;
		#size-cells = <0x02>;
		ranges;

		/*
		 * HIF/PDMA coherent pool for the WLAN driver.  The CONNSYS MCU
		 * can only reach this fixed window, and the stock Android kernel
		 * creates the very same 6 MiB DMA pool at 0xbf000000.
		 */
		wifi_emi: wifi@bf000000 {
			compatible = "shared-dma-pool";
			reg = <0x00 0xbf000000 0x00 0x600000>;
			no-map;
		};

		consys_emi: consys-emi@7d000000 {
			compatible = "shared-dma-pool";
			reg = <0x00 0x7d000000 0x00 0x600000>;
			no-map;
		};

		sspm_ap@9f560000 {
			reg = <0x00 0x9f560000 0x00 0x110000>;
			no-map;
		};

		ap_md_c_smem@8c000000 {
			reg = <0x00 0x8c000000 0x00 0x16a0000>;
			no-map;
		};

		ap_md_nc_smem@8e000000 {
			reg = <0x00 0x8e000000 0x00 0xe00000>;
			no-map;
		};

		md_mem@e3200000 {
			reg = <0x00 0xe3200000 0x00 0xe00000>;
			no-map;
		};

		md_mem4@dc000000 {
			reg = <0x00 0xdc000000 0x00 0x14b0000>;
			no-map;
		};

		ccci_tag@bf9f0000 {
			reg = <0x00 0xbf9f0000 0x00 0x10000>;
			no-map;
		};

		scp_share@8f000000 {
			reg = <0x00 0x8f000000 0x00 0x5a0000>;
			compatible = "shared-dma-pool";
			no-map;
		};

		scp@bfa00000 {
			reg = <0x00 0xbfa00000 0x00 0x400000>;
			no-map;
		};

		dfdmcu_dump@fd000000 {
			reg = <0x00 0xfd000000 0x00 0x100000>;
			no-map;
		};

		crypto_hw@48401000 {
			reg = <0x00 0x48401000 0x00 0x1000>;
			no-map;
		};

		tee@70000000 {
			reg = <0x00 0x70000000 0x00 0x6000000>;
			no-map;
		};

		tee_sec@7de00000 {
			reg = <0x00 0x7de00000 0x00 0x800000>;
			no-map;
		};

		mcupm@7feb0000 {
			reg = <0x00 0x7feb0000 0x00 0x100000>;
			no-map;
		};

		sspm@9fe70000 {
			reg = <0x00 0x9fe70000 0x00 0x180000>;
			no-map;
		};

		bl31@48200000 {
			reg = <0x00 0x48200000 0x00 0x200000>;
			no-map;
		};

		/*
		 * LK display memory: three 1088x2400x4 buffers, the middle one
		 * (display-fb) is what LK scans out and what we keep scanning.
		 */
		lkfb0@fe0c8000 {
			reg = <0x00 0xfe0c8000 0x00 0x9f6000>;
			no-map;
		};

		display_fb: display-fb@feabe000 {
			compatible = "shared-dma-pool";
			reg = <0x00 0xfeabe000 0x00 0x1539000>;
			no-map;
		};

		aee_lk@50700000 {
			reg = <0x00 0x50700000 0x00 0x800000>;
			no-map;
		};

		pl_drambuf@48500000 {
			reg = <0x00 0x48500000 0x00 0x100000>;
			no-map;
		};

		unmap@7e800000 {
			reg = <0x00 0x7e800000 0x00 0x400000>;
			no-map;
		};

		gz@7ec00000 {
			reg = <0x00 0x7ec00000 0x00 0x1200000>;
			no-map;
		};

		emi_mbist@7ffff000 {
			reg = <0x00 0x7ffff000 0x00 0x1000>;
			no-map;
		};

		dram-controller1@3ffff000 {
			reg = <0x02 0x3ffff000 0x00 0x1000>;
			no-map;
		};

		dram-controller0@3ffff000 {
			reg = <0x01 0x3ffff000 0x00 0x1000>;
			no-map;
		};

		ramoops@9f800000 {
			compatible = "ramoops";
			reg = <0x00 0x9f800000 0x00 0x00100000>;
			record-size = <0x00040000>;
			console-size = <0x00040000>;
			ftrace-size = <0x00040000>;
			pmsg-size = <0x00040000>;
			no-map;
		};
	};
};
